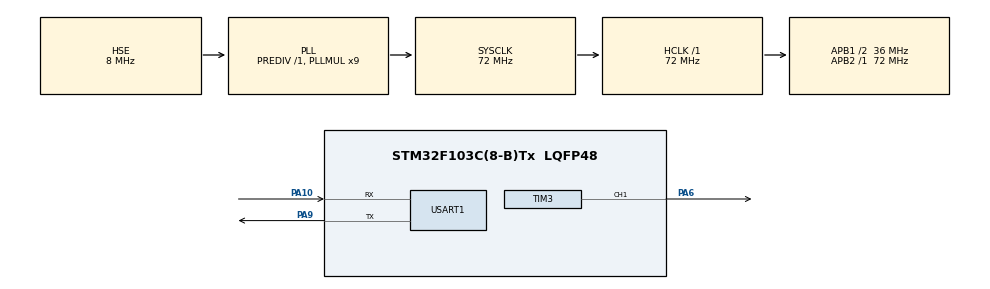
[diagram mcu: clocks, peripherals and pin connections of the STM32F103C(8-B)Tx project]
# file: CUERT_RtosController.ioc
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FREERTOS.Tasks01=COMMAND_RX,40,256,StartCommandRxTask,Default,NULL,Dynamic,NULL,NULL;ACTUATE,32,256,StartActuateTask,Default,NULL,Dynamic,NULL,NULL;WATCHDOG,24,128,StartWatchdogTask,Default,NULL,Dynamic,NULL,NULL;STATUS,8,256,StartStatusTask,Default,NULL,Dynamic,NULL,NULL
FREERTOS.configTOTAL_HEAP_SIZE=8192
Mcu.Family=STM32F1
Mcu.Name=STM32F103C(8-B)Tx
Mcu.Package=LQFP48
NVIC.PriorityGroup=NVIC_PRIORITYGROUP_4
NVIC.TIM1_UP_IRQn=true\:15\:0\:false\:false\:true\:false\:false\:true\:true
NVIC.TimeBase=TIM1_UP_IRQn
NVIC.TimeBaseIP=TIM1
NVIC.USART1_IRQn=true\:5\:0\:false\:false\:true\:true\:true\:true\:true
PA10.Mode=Asynchronous
PA10.Signal=USART1_RX
PA13.Mode=Serial_Wire
PA13.Signal=SYS_JTMS-SWDIO
PA14.Mode=Serial_Wire
PA14.Signal=SYS_JTCK-SWCLK
PA6.Signal=S_TIM3_CH1
PA9.Mode=Asynchronous
PA9.Signal=USART1_TX
PD0-OSC_IN.Mode=HSE-External-Oscillator
PD0-OSC_IN.Signal=RCC_OSC_IN
PD1-OSC_OUT.Mode=HSE-External-Oscillator
PD1-OSC_OUT.Signal=RCC_OSC_OUT
ProjectManager.HeapSize=0x200
ProjectManager.StackSize=0x400
ProjectManager.TargetToolchain=CMake
RCC.AHBFreq_Value=72000000
RCC.APB1CLKDivider=RCC_HCLK_DIV2
RCC.APB1Freq_Value=36000000
RCC.APB1TimFreq_Value=72000000
RCC.APB2Freq_Value=72000000
RCC.APB2TimFreq_Value=72000000
RCC.HCLKFreq_Value=72000000
RCC.PLLMUL=RCC_PLL_MUL9
RCC.PLLSourceVirtual=RCC_PLLSOURCE_HSE
RCC.SYSCLKFreq_VALUE=72000000
RCC.SYSCLKSource=RCC_SYSCLKSOURCE_PLLCLK
RCC.USBFreq_Value=72000000
SH.S_TIM3_CH1.0=TIM3_CH1,PWM Generation1 CH1
TIM3.Channel-PWM\ Generation1\ CH1=TIM_CHANNEL_1
TIM3.Period=999
TIM3.Prescaler=71
USART1.VirtualMode=VM_ASYNC
VP_FREERTOS_VS_CMSIS_V2.Mode=CMSIS_V2
VP_SYS_VS_tim1.Mode=TIM1
VP_TIM3_VS_ClockSourceINT.Mode=Internal
board=custom

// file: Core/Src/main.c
/* USER CODE BEGIN Header */
/**
  ******************************************************************************
  * @file           : main.c
  * @brief          : Main program body
  ******************************************************************************
  * @attention
  *
  * Copyright (c) 2026 STMicroelectronics.
  * All rights reserved.
  *
  * This software is licensed under terms that can be found in the LICENSE file
  * in the root directory of this software component.
  * If no LICENSE file comes with this software, it is provided AS-IS.
  *
  ******************************************************************************
  */
/* USER CODE END Header */
#include "main.h"
#include "cmsis_os.h"

/* USER CODE BEGIN Includes */
#include "cuert_app.h"

/* USER CODE END Includes */

TIM_HandleTypeDef htim3;

UART_HandleTypeDef huart1;

/* Definitions for COMMAND_RX */
osThreadId_t COMMAND_RXHandle;
const osThreadAttr_t COMMAND_RX_attributes = {
  .name = "COMMAND_RX",
  .stack_size = 256 * 4,
  .priority = (osPriority_t) osPriorityHigh,
};
/* Definitions for ACTUATE */
osThreadId_t ACTUATEHandle;
const osThreadAttr_t ACTUATE_attributes = {
  .name = "ACTUATE",
  .stack_size = 256 * 4,
  .priority = (osPriority_t) osPriorityAboveNormal,
};
/* Definitions for WATCHDOG */
osThreadId_t WATCHDOGHandle;
const osThreadAttr_t WATCHDOG_attributes = {
  .name = "WATCHDOG",
  .stack_size = 128 * 4,
  .priority = (osPriority_t) osPriorityNormal,
};
/* Definitions for STATUS */
osThreadId_t STATUSHandle;
const osThreadAttr_t STATUS_attributes = {
  .name = "STATUS",
  .stack_size = 256 * 4,
  .priority = (osPriority_t) osPriorityLow,
};
/* USER CODE BEGIN PV */
osMessageQueueId_t commandQueueHandle;
osMutexId_t appStateMutexHandle;
osMutexId_t appTxMutexHandle;
/* STARTUP_WAIT: safe/disarmed, with a 500 ms communication grace period. */
AppState_t appState = {0};
static const osMutexAttr_t appStateMutex_attributes = {
  .name = "appState",
  .attr_bits = osMutexPrioInherit
};
static const osMutexAttr_t appTxMutex_attributes = {
  .name = "appTx",
  .attr_bits = osMutexPrioInherit
};
static const osMessageQueueAttr_t commandQueue_attributes = {
  .name = "commandFIFO"
};

/* USER CODE END PV */

void SystemClock_Config(void);
static void MX_GPIO_Init(void);
static void MX_TIM3_Init(void);
static void MX_USART1_UART_Init(void);
void StartCommandRxTask(void *argument);
void StartActuateTask(void *argument);
void StartWatchdogTask(void *argument);
void StartStatusTask(void *argument);

int main(void)
{

  /* MCU Configuration--------------------------------------------------------*/

  /* Reset of all peripherals, Initializes the Flash interface and the Systick. */
  HAL_Init();

  /* Configure the system clock */
  SystemClock_Config();

  /* Initialize all configured peripherals */
  MX_GPIO_Init();
  MX_TIM3_Init();
  MX_USART1_UART_Init();

  /* Init scheduler */
  osKernelInitialize();

  /* USER CODE BEGIN RTOS_MUTEX */
  appStateMutexHandle = osMutexNew(&appStateMutex_attributes);
  if (appStateMutexHandle == NULL)
  {
    Error_Handler();
  }
  appTxMutexHandle = osMutexNew(&appTxMutex_attributes);
  if (appTxMutexHandle == NULL)
  {
    Error_Handler();
  }
  /* USER CODE END RTOS_MUTEX */

  /* USER CODE BEGIN RTOS_QUEUES */
  commandQueueHandle = osMessageQueueNew(APP_COMMAND_QUEUE_LENGTH,
                                         sizeof(Command_t),
                                         &commandQueue_attributes);
  if (commandQueueHandle == NULL)
  {
    Error_Handler();
  }
  /* USER CODE END RTOS_QUEUES */

  /* Create the thread(s) */
  /* creation of COMMAND_RX */
  COMMAND_RXHandle = osThreadNew(StartCommandRxTask, NULL, &COMMAND_RX_attributes);

  /* creation of ACTUATE */
  ACTUATEHandle = osThreadNew(StartActuateTask, NULL, &ACTUATE_attributes);

  /* creation of WATCHDOG */
  WATCHDOGHandle = osThreadNew(StartWatchdogTask, NULL, &WATCHDOG_attributes);

  /* creation of STATUS */
  STATUSHandle = osThreadNew(StartStatusTask, NULL, &STATUS_attributes);

  /* USER CODE BEGIN RTOS_THREADS */
  if (COMMAND_RXHandle == NULL || ACTUATEHandle == NULL ||
      WATCHDOGHandle == NULL || STATUSHandle == NULL)
  {
    Error_Handler();
  }
  /* USER CODE END RTOS_THREADS */

  /* USER CODE BEGIN RTOS_EVENTS */
  /* Bootstrap time reference for the initial 500 ms grace period.
   * has_valid_command remains false until COMMAND_RX accepts a command. */
  appState.last_valid_command_timestamp_ms = HAL_GetTick();
  /* USER CODE END RTOS_EVENTS */

  /* Start scheduler */
  osKernelStart();

  /* We should never get here as control is now taken by the scheduler */

  /* Infinite loop */
  while (1)
  {

  }
}

void SystemClock_Config(void)
{
  RCC_OscInitTypeDef RCC_OscInitStruct = {0};
  RCC_ClkInitTypeDef RCC_ClkInitStruct = {0};

  /** Initializes the RCC Oscillators according to the specified parameters
  * in the RCC_OscInitTypeDef structure.
  */
  RCC_OscInitStruct.OscillatorType = RCC_OSCILLATORTYPE_HSE;
  RCC_OscInitStruct.HSEState = RCC_HSE_ON;
  RCC_OscInitStruct.HSEPredivValue = RCC_HSE_PREDIV_DIV1;
  RCC_OscInitStruct.HSIState = RCC_HSI_ON;
  RCC_OscInitStruct.PLL.PLLState = RCC_PLL_ON;
  RCC_OscInitStruct.PLL.PLLSource = RCC_PLLSOURCE_HSE;
  RCC_OscInitStruct.PLL.PLLMUL = RCC_PLL_MUL9;
  if (HAL_RCC_OscConfig(&RCC_OscInitStruct) != HAL_OK)
  {
    Error_Handler();
  }

  /** Initializes the CPU, AHB and APB buses clocks
  */
  RCC_ClkInitStruct.ClockType = RCC_CLOCKTYPE_HCLK|RCC_CLOCKTYPE_SYSCLK
                              |RCC_CLOCKTYPE_PCLK1|RCC_CLOCKTYPE_PCLK2;
  RCC_ClkInitStruct.SYSCLKSource = RCC_SYSCLKSOURCE_PLLCLK;
  RCC_ClkInitStruct.AHBCLKDivider = RCC_SYSCLK_DIV1;
  RCC_ClkInitStruct.APB1CLKDivider = RCC_HCLK_DIV2;
  RCC_ClkInitStruct.APB2CLKDivider = RCC_HCLK_DIV1;

  if (HAL_RCC_ClockConfig(&RCC_ClkInitStruct, FLASH_LATENCY_2) != HAL_OK)
  {
    Error_Handler();
  }
}

static void MX_TIM3_Init(void)
{

  TIM_ClockConfigTypeDef sClockSourceConfig = {0};
  TIM_MasterConfigTypeDef sMasterConfig = {0};
  TIM_OC_InitTypeDef sConfigOC = {0};

  htim3.Instance = TIM3;
  htim3.Init.Prescaler = 71;
  htim3.Init.CounterMode = TIM_COUNTERMODE_UP;
  htim3.Init.Period = 999;
  htim3.Init.ClockDivision = TIM_CLOCKDIVISION_DIV1;
  htim3.Init.AutoReloadPreload = TIM_AUTORELOAD_PRELOAD_DISABLE;
  if (HAL_TIM_Base_Init(&htim3) != HAL_OK)
  {
    Error_Handler();
  }
  sClockSourceConfig.ClockSource = TIM_CLOCKSOURCE_INTERNAL;
  if (HAL_TIM_ConfigClockSource(&htim3, &sClockSourceConfig) != HAL_OK)
  {
    Error_Handler();
  }
  if (HAL_TIM_PWM_Init(&htim3) != HAL_OK)
  {
    Error_Handler();
  }
  sMasterConfig.MasterOutputTrigger = TIM_TRGO_RESET;
  sMasterConfig.MasterSlaveMode = TIM_MASTERSLAVEMODE_DISABLE;
  if (HAL_TIMEx_MasterConfigSynchronization(&htim3, &sMasterConfig) != HAL_OK)
  {
    Error_Handler();
  }
  sConfigOC.OCMode = TIM_OCMODE_PWM1;
  sConfigOC.Pulse = 0;
  sConfigOC.OCPolarity = TIM_OCPOLARITY_HIGH;
  sConfigOC.OCFastMode = TIM_OCFAST_DISABLE;
  if (HAL_TIM_PWM_ConfigChannel(&htim3, &sConfigOC, TIM_CHANNEL_1) != HAL_OK)
  {
    Error_Handler();
  }
  HAL_TIM_MspPostInit(&htim3);

}

static void MX_USART1_UART_Init(void)
{

  huart1.Instance = USART1;
  huart1.Init.BaudRate = 115200;
  huart1.Init.WordLength = UART_WORDLENGTH_8B;
  huart1.Init.StopBits = UART_STOPBITS_1;
  huart1.Init.Parity = UART_PARITY_NONE;
  huart1.Init.Mode = UART_MODE_TX_RX;
  huart1.Init.HwFlowCtl = UART_HWCONTROL_NONE;
  huart1.Init.OverSampling = UART_OVERSAMPLING_16;
  if (HAL_UART_Init(&huart1) != HAL_OK)
  {
    Error_Handler();
  }

}

static void MX_GPIO_Init(void)
{

  /* GPIO Ports Clock Enable */
  __HAL_RCC_GPIOD_CLK_ENABLE();
  __HAL_RCC_GPIOA_CLK_ENABLE();

  /* USER CODE BEGIN MX_GPIO_Init_2 */
  GPIO_InitTypeDef watchdogLed = {0};
  __HAL_RCC_GPIOC_CLK_ENABLE();
  /* Set the output latch before enabling the driver: active-low LED OFF. */
  HAL_GPIO_WritePin(GPIOC, GPIO_PIN_13, GPIO_PIN_SET);
  watchdogLed.Pin = GPIO_PIN_13;
  watchdogLed.Mode = GPIO_MODE_OUTPUT_PP;
  watchdogLed.Pull = GPIO_NOPULL;
  watchdogLed.Speed = GPIO_SPEED_FREQ_LOW;
  HAL_GPIO_Init(GPIOC, &watchdogLed);

  /* USER CODE END MX_GPIO_Init_2 */
}

void StartCommandRxTask(void *argument)
{
  /* USER CODE BEGIN 5 */
  AppCommandRxRun();
  /* USER CODE END 5 */
}

void StartActuateTask(void *argument)
{
  /* USER CODE BEGIN StartActuateTask */
  AppActuateRun();
  /* USER CODE END StartActuateTask */
}

void StartWatchdogTask(void *argument)
{
  /* USER CODE BEGIN StartWatchdogTask */
  AppWatchdogRun();
  /* USER CODE END StartWatchdogTask */
}

void StartStatusTask(void *argument)
{
  /* USER CODE BEGIN StartStatusTask */
  AppStatusRun();
  /* USER CODE END StartStatusTask */
}

void HAL_TIM_PeriodElapsedCallback(TIM_HandleTypeDef *htim)
{
  if (htim->Instance == TIM1)
  {
    HAL_IncTick();
  }
}

void Error_Handler(void)
{
  __disable_irq();
  while (1)
  {
  }
}
